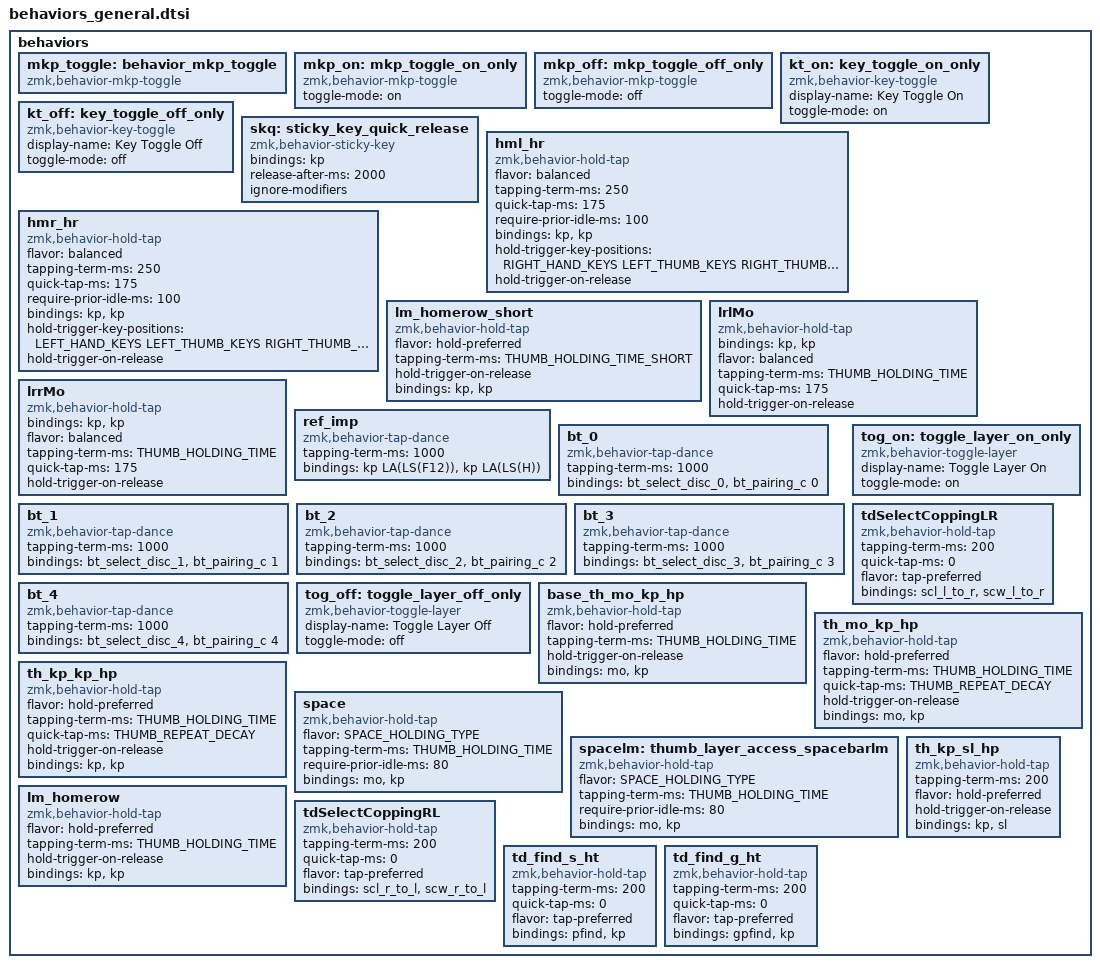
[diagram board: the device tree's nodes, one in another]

#define THUMB_HOLDING_TIME 220 // THUMB_HOLDING_TIME defines how long you need to hold (milliseconds) a thumb key to activate a layer.  Shorter holds are treated as taps.
#define THUMB_HOLDING_TIME_SHORT 150
#define THUMB_REPEAT_DECAY_BASE 0 // "tap then hold" for key auto-repeat
#define THUMB_REPEAT_DECAY 190 // "tap then hold" for key auto-repeat
#define SPACE_HOLDING_TYPE "balanced"

        //     0  1  2  3  4         5  6  7  8  9
        //    10 11 12 13 14        15 16 17 18 19
        //    20 21 22 23 24        25 26 27 28 29 
        //          30 31 32        33 34 

        //     0  1  2  3  4         5  6  7  8  9
        //    10 11 12 13 14        15 16 17 18 19
        //    20 21 22 23 24        25 26 27 28 29 
        //    30 31 32 33 34 35  36 37          38

        //     0  1  2  3  4     5  6  7  8  9
        //    10 11 12 13 14    15 16 17 18 19
        //20  21 22 23 24 25    26 27 28 29 30  31
        //        32 33 34         35 36 37


#define LEFT_HAND_KEYS    0  1  2  3  4  \
                         10 11 12 13 14  \
                         20 21 22 23 24  
                        
#define RIGHT_HAND_KEYS      5  6  7  8  9 \
                            15 16 17 18 19 \
                            25 26 27 28 29 
                         
#define LEFT_THUMB_KEYS   30 31 32    

#define RIGHT_THUMB_KEYS   33 34 

   
   behaviors {

        mkp_toggle: behavior_mkp_toggle {
            compatible = "zmk,behavior-mkp-toggle";
            #binding-cells = <1>;
        };

        mkp_on: mkp_toggle_on_only {
            compatible = "zmk,behavior-mkp-toggle";
            #binding-cells = <1>;
            toggle-mode = "on";   // o "on"
        };

        mkp_off: mkp_toggle_off_only {
            compatible = "zmk,behavior-mkp-toggle";
            #binding-cells = <1>;
            toggle-mode = "off";   // o "on"
        };

        kt_on: key_toggle_on_only {
            compatible = "zmk,behavior-key-toggle";
            #binding-cells = <1>;
            display-name = "Key Toggle On";
            toggle-mode = "on";
        };


        kt_off: key_toggle_off_only {
            compatible = "zmk,behavior-key-toggle";
            #binding-cells = <1>;
            display-name = "Key Toggle Off";
            toggle-mode = "off";
        };

      skq: sticky_key_quick_release {
        compatible = "zmk,behavior-sticky-key";
        #binding-cells = <1>;
        bindings = <&kp>;
        release-after-ms = <2000>;
        //quick-release;
        ignore-modifiers;
      };

        hml_hr: hml_hr {
            compatible = "zmk,behavior-hold-tap";
            #binding-cells = <2>;
            flavor = "balanced";
            tapping-term-ms = <250>;                                 
            quick-tap-ms = <175>;
            require-prior-idle-ms = <100>;
            bindings = <&kp>, <&kp>;
            hold-trigger-key-positions = <RIGHT_HAND_KEYS LEFT_THUMB_KEYS RIGHT_THUMB_KEYS>;
            hold-trigger-on-release;
        };

        hmr_hr: hmr_hr {
            compatible = "zmk,behavior-hold-tap";
            #binding-cells = <2>;
            flavor = "balanced";
            tapping-term-ms = <250>;
            quick-tap-ms = <175>;
            require-prior-idle-ms = <100>;
            bindings = <&kp>, <&kp>;
            hold-trigger-key-positions = <LEFT_HAND_KEYS LEFT_THUMB_KEYS RIGHT_THUMB_KEYS>;
            hold-trigger-on-release;
        };

        lm_homerow_short: lm_homerow_short {
            compatible = "zmk,behavior-hold-tap";
            flavor = "hold-preferred";
            tapping-term-ms = <THUMB_HOLDING_TIME_SHORT>;
            #binding-cells = <2>;
            hold-trigger-on-release;
            bindings = <&kp>, <&kp>;
        };

        lrlMo: lrlMo {
            compatible = "zmk,behavior-hold-tap";
            bindings = <&kp>, <&kp>;
            #binding-cells = <2>;
            flavor = "balanced";
            tapping-term-ms = <THUMB_HOLDING_TIME>;
            quick-tap-ms = <175>;
            hold-trigger-on-release;
        };

        lrrMo: lrrMo {
            compatible = "zmk,behavior-hold-tap";
            bindings = <&kp>, <&kp>;
            #binding-cells = <2>; 
            flavor = "balanced";
            tapping-term-ms = <THUMB_HOLDING_TIME>;
            quick-tap-ms = <175>;
            hold-trigger-on-release;
        };

        ref_imp: ref_imp {
            compatible = "zmk,behavior-tap-dance";
            #binding-cells = <0>;
            tapping-term-ms = <1000>;
            bindings = <&kp LA(LS(F12))>, <&kp LA(LS(H))>;
        };
        
        bt_0: bt_0 {
            compatible = "zmk,behavior-tap-dance";
            #binding-cells = <0>;
            tapping-term-ms = <1000>;
            bindings = <&bt_select_disc_0>, <&bt_pairing_c 0>;
        };

        bt_1: bt_1 {
            compatible = "zmk,behavior-tap-dance";
            #binding-cells = <0>;
            tapping-term-ms = <1000>;
            bindings = <&bt_select_disc_1>, <&bt_pairing_c 1>;
        };

        bt_2: bt_2 {
            compatible = "zmk,behavior-tap-dance";
            #binding-cells = <0>;
            tapping-term-ms = <1000>;
            bindings = <&bt_select_disc_2>, <&bt_pairing_c 2>;
        };

        bt_3: bt_3 {
            compatible = "zmk,behavior-tap-dance";
            #binding-cells = <0>;
            tapping-term-ms = <1000>;
            bindings = <&bt_select_disc_3>, <&bt_pairing_c 3>;
        };

        bt_4: bt_4 {
            compatible = "zmk,behavior-tap-dance";
            #binding-cells = <0>;
            tapping-term-ms = <1000>;
            bindings = <&bt_select_disc_4>, <&bt_pairing_c 4>;
        };

        tog_on: toggle_layer_on_only {
            compatible = "zmk,behavior-toggle-layer";
            #binding-cells = <1>;
            display-name = "Toggle Layer On";
            toggle-mode = "on";
        };

        tog_off: toggle_layer_off_only {
            compatible = "zmk,behavior-toggle-layer";
            #binding-cells = <1>;
            display-name = "Toggle Layer Off";
            toggle-mode = "off";
        };


        tdSelectCoppingLR: tdSelectCoppingLR {
            compatible = "zmk,behavior-hold-tap";
            #binding-cells = <2>;
            tapping-term-ms = <200>;
            quick-tap-ms = <0>;
            flavor = "tap-preferred";
            bindings = <&scl_l_to_r>, <&scw_l_to_r>;
        };

        base_th_mo_kp_hp: base_th_mo_kp_hp {
            compatible = "zmk,behavior-hold-tap";
            flavor = "hold-preferred";
            tapping-term-ms = <THUMB_HOLDING_TIME>;
            //quick-tap-ms = <THUMB_REPEAT_DECAY_BASE>; // enable repeat
            hold-trigger-on-release; // wait for other home row mods
            #binding-cells = <2>;
            bindings = <&mo>, <&kp>;
        };

        th_mo_kp_hp: th_mo_kp_hp {
            compatible = "zmk,behavior-hold-tap";
            flavor = "hold-preferred";
            tapping-term-ms = <THUMB_HOLDING_TIME>;
            quick-tap-ms = <THUMB_REPEAT_DECAY>; // enable repeat
            hold-trigger-on-release; // wait for other home row mods
            #binding-cells = <2>;
            bindings = <&mo>, <&kp>;
        };

        th_kp_kp_hp: th_kp_kp_hp {
            compatible = "zmk,behavior-hold-tap";
            flavor = "hold-preferred";
            tapping-term-ms = <THUMB_HOLDING_TIME>;
            quick-tap-ms = <THUMB_REPEAT_DECAY>; // enable repeat
            #binding-cells = <2>;
            hold-trigger-on-release;
            bindings = <&kp>, <&kp>;
        };

        space: space {
            compatible = "zmk,behavior-hold-tap";
            flavor = SPACE_HOLDING_TYPE;
            tapping-term-ms = <THUMB_HOLDING_TIME>;
            //quick-tap-ms = <THUMB_REPEAT_DECAY>; // enable repeat
            #binding-cells = <2>;
            require-prior-idle-ms = <80>;
            bindings = <&mo>, <&kp>;
        };

        spacelm: thumb_layer_access_spacebarlm {
            compatible = "zmk,behavior-hold-tap";
            flavor = SPACE_HOLDING_TYPE;
            tapping-term-ms = <THUMB_HOLDING_TIME>;
            #binding-cells = <2>;
            require-prior-idle-ms = <80>;
            bindings = <&mo>, <&kp>;
        };

        th_kp_sl_hp: th_kp_sl_hp {
            compatible = "zmk,behavior-hold-tap";
            #binding-cells = <2>;
            tapping-term-ms = <200>;    // <---[[moderate duration]]
            flavor = "hold-preferred";
            hold-trigger-on-release;
            bindings = <&kp>, <&sl>;
        };

        lm_homerow: lm_homerow {
            compatible = "zmk,behavior-hold-tap";
            flavor = "hold-preferred";
            tapping-term-ms = <THUMB_HOLDING_TIME>;
            #binding-cells = <2>;
            hold-trigger-on-release;
            bindings = <&kp>, <&kp>;
        };

        tdSelectCoppingRL: tdSelectCoppingRL {
            compatible = "zmk,behavior-hold-tap";
            #binding-cells = <2>;
            tapping-term-ms = <200>;
            quick-tap-ms = <0>;
            flavor = "tap-preferred";
            bindings = <&scl_r_to_l>, <&scw_r_to_l>;
        };

        td_find_s_ht: td_find_s_ht {
            compatible = "zmk,behavior-hold-tap";
            #binding-cells = <2>;
            tapping-term-ms = <200>;
            quick-tap-ms = <0>;
            flavor = "tap-preferred";
            bindings = <&pfind>, <&kp>;
        };

        td_find_g_ht: td_find_g_ht {
            compatible = "zmk,behavior-hold-tap";
            #binding-cells = <2>;
            tapping-term-ms = <200>;
            quick-tap-ms = <0>;
            flavor = "tap-preferred";
            bindings = <&gpfind>, <&kp>;
        };

    };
